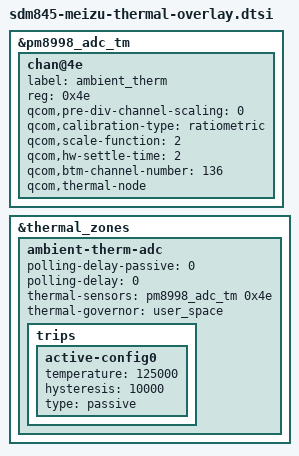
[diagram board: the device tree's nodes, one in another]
/* Copyright (c) 2022, MeizuCustoms enthusiasts
 *
 * This program is free software; you can redistribute it and/or modify
 * it under the terms of the GNU General Public License version 2 and
 * only version 2 as published by the Free Software Foundation.
 *
 * This program is distributed in the hope that it will be useful,
 * but WITHOUT ANY WARRANTY; without even the implied warranty of
 * MERCHANTABILITY or FITNESS FOR A PARTICULAR PURPOSE.  See the
 * GNU General Public License for more details.
 */

&pm8998_adc_tm {
    chan@4e {
        label = "ambient_therm";
        reg = <0x4e>;
        qcom,pre-div-channel-scaling = <0>;
        qcom,calibration-type = "ratiometric";
        qcom,scale-function = <2>;
        qcom,hw-settle-time = <2>;
        qcom,btm-channel-number = <136>;
        qcom,thermal-node;
    };
};

&thermal_zones {
    ambient-therm-adc {
        polling-delay-passive = <0>;
        polling-delay = <0>;
        thermal-sensors = <&pm8998_adc_tm 0x4e>;
        thermal-governor = "user_space";

        trips {

            active-config0 {
                temperature = <125000>;
                hysteresis = <10000>;
                type = "passive";
            };
        };
    };
};
